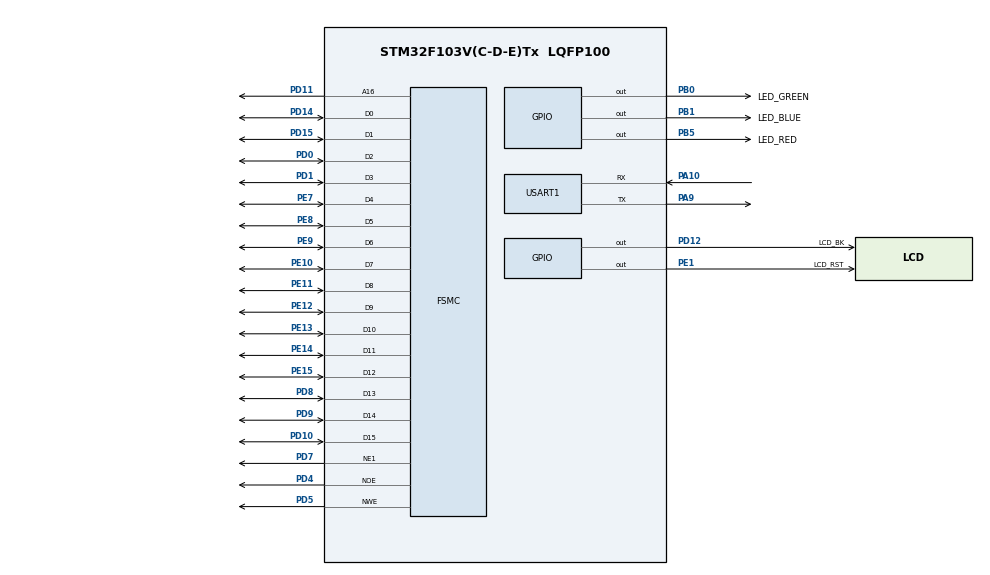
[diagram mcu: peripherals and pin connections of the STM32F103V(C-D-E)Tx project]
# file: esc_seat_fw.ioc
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Dma.Request0=USART1_RX
Dma.USART1_RX.0.Direction=DMA_PERIPH_TO_MEMORY
Dma.USART1_RX.0.Instance=DMA1_Channel5
Dma.USART1_RX.0.MemDataAlignment=DMA_MDATAALIGN_BYTE
Dma.USART1_RX.0.MemInc=DMA_MINC_ENABLE
Dma.USART1_RX.0.Mode=DMA_CIRCULAR
Dma.USART1_RX.0.PeriphDataAlignment=DMA_PDATAALIGN_BYTE
Dma.USART1_RX.0.PeriphInc=DMA_PINC_DISABLE
Dma.USART1_RX.0.Priority=DMA_PRIORITY_LOW
FSMC.AddressSetupTime1=1
FSMC.BusTurnAroundDuration1=0
FSMC.DataSetupTime1=1
Mcu.Family=STM32F1
Mcu.Name=STM32F103V(C-D-E)Tx
Mcu.Package=LQFP100
NVIC.DMA1_Channel5_IRQn=true\:0\:0\:false\:false\:true\:false\:true\:true
NVIC.PriorityGroup=NVIC_PRIORITYGROUP_4
NVIC.USART1_IRQn=true\:0\:0\:false\:false\:true\:true\:true\:true
OSC_IN.Mode=HSE-External-Oscillator
OSC_IN.Signal=RCC_OSC_IN
OSC_OUT.Mode=HSE-External-Oscillator
OSC_OUT.Signal=RCC_OSC_OUT
PA10.Mode=Asynchronous
PA10.Signal=USART1_RX
PA13.Mode=Serial_Wire
PA13.Signal=SYS_JTMS-SWDIO
PA14.Mode=Serial_Wire
PA14.Signal=SYS_JTCK-SWCLK
PA9.Mode=Asynchronous
PA9.Signal=USART1_TX
PB0.GPIO_Label=LED_GREEN
PB0.PinState=GPIO_PIN_SET
PB0.Signal=GPIO_Output
PB1.GPIO_Label=LED_BLUE
PB1.PinState=GPIO_PIN_SET
PB1.Signal=GPIO_Output
PB5.GPIO_Label=LED_RED
PB5.PinState=GPIO_PIN_SET
PB5.Signal=GPIO_Output
PD0.Mode=16b-d1
PD0.Signal=FSMC_D2
PD1.Mode=16b-d1
PD1.Signal=FSMC_D3
PD10.Mode=16b-d1
PD10.Signal=FSMC_D15
PD11.Mode=A16_1
PD11.Signal=FSMC_A16
PD12.GPIO_Label=LCD_BK
PD12.PinState=GPIO_PIN_SET
PD12.Signal=GPIO_Output
PD14.Mode=16b-d1
PD14.Signal=FSMC_D0
PD15.Mode=16b-d1
PD15.Signal=FSMC_D1
PD4.Mode=Lcd1
PD4.Signal=FSMC_NOE
PD5.Mode=Lcd1
PD5.Signal=FSMC_NWE
PD7.Mode=NorPsramChipSelect1_1
PD7.Signal=FSMC_NE1
PD8.Mode=16b-d1
PD8.Signal=FSMC_D13
PD9.Mode=16b-d1
PD9.Signal=FSMC_D14
PE1.GPIO_Label=LCD_RST
PE1.Signal=GPIO_Output
PE10.Mode=16b-d1
PE10.Signal=FSMC_D7
PE11.Mode=16b-d1
PE11.Signal=FSMC_D8
PE12.Mode=16b-d1
PE12.Signal=FSMC_D9
PE13.Mode=16b-d1
PE13.Signal=FSMC_D10
PE14.Mode=16b-d1
PE14.Signal=FSMC_D11
PE15.Mode=16b-d1
PE15.Signal=FSMC_D12
PE7.Mode=16b-d1
PE7.Signal=FSMC_D4
PE8.Mode=16b-d1
PE8.Signal=FSMC_D5
PE9.Mode=16b-d1
PE9.Signal=FSMC_D6
ProjectManager.HeapSize=0x200
ProjectManager.StackSize=0x400
ProjectManager.TargetToolchain=CMake
RCC.APB1Freq_Value=8000000
RCC.APB2Freq_Value=8000000
USART1.VirtualMode=VM_ASYNC
board=custom

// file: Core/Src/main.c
/* USER CODE BEGIN Header */
/**
  ******************************************************************************
  * @file           : main.c
  * @brief          : Main program body
  ******************************************************************************
  * @attention
  *
  * Copyright (c) 2026 STMicroelectronics.
  * All rights reserved.
  *
  * This software is licensed under terms that can be found in the LICENSE file
  * in the root directory of this software component.
  * If no LICENSE file comes with this software, it is provided AS-IS.
  *
  ******************************************************************************
  */
/* USER CODE END Header */
#include "main.h"

/* USER CODE BEGIN Includes */
#include "AppSystem.h"
#include "Scheduler.h"
/* USER CODE END Includes */

UART_HandleTypeDef huart1;
DMA_HandleTypeDef hdma_usart1_rx;

SRAM_HandleTypeDef hsram1;

void SystemClock_Config(void);
static void MX_GPIO_Init(void);
static void MX_DMA_Init(void);
static void MX_USART1_UART_Init(void);
static void MX_FSMC_Init(void);

int main(void)
{

  /* MCU Configuration--------------------------------------------------------*/

  /* Reset of all peripherals, Initializes the Flash interface and the Systick. */
  HAL_Init();

  /* Configure the system clock */
  SystemClock_Config();

  /* Initialize all configured peripherals */
  MX_GPIO_Init();
  MX_DMA_Init();
  MX_USART1_UART_Init();
  MX_FSMC_Init();
  /* USER CODE BEGIN 2 */
  AppSystem_Init();
  /* USER CODE END 2 */

  /* Infinite loop */
  while (1)
  {

    /* USER CODE BEGIN 3 */
    Scheduler_MainFunction();

  }
  /* USER CODE END 3 */
}

void SystemClock_Config(void)
{
  RCC_OscInitTypeDef RCC_OscInitStruct = {0};
  RCC_ClkInitTypeDef RCC_ClkInitStruct = {0};

  /** Initializes the RCC Oscillators according to the specified parameters
  * in the RCC_OscInitTypeDef structure.
  */
  RCC_OscInitStruct.OscillatorType = RCC_OSCILLATORTYPE_HSI;
  RCC_OscInitStruct.HSIState = RCC_HSI_ON;
  RCC_OscInitStruct.HSICalibrationValue = RCC_HSICALIBRATION_DEFAULT;
  RCC_OscInitStruct.PLL.PLLState = RCC_PLL_NONE;
  if (HAL_RCC_OscConfig(&RCC_OscInitStruct) != HAL_OK)
  {
    Error_Handler();
  }

  /** Initializes the CPU, AHB and APB buses clocks
  */
  RCC_ClkInitStruct.ClockType = RCC_CLOCKTYPE_HCLK|RCC_CLOCKTYPE_SYSCLK
                              |RCC_CLOCKTYPE_PCLK1|RCC_CLOCKTYPE_PCLK2;
  RCC_ClkInitStruct.SYSCLKSource = RCC_SYSCLKSOURCE_HSI;
  RCC_ClkInitStruct.AHBCLKDivider = RCC_SYSCLK_DIV1;
  RCC_ClkInitStruct.APB1CLKDivider = RCC_HCLK_DIV1;
  RCC_ClkInitStruct.APB2CLKDivider = RCC_HCLK_DIV1;

  if (HAL_RCC_ClockConfig(&RCC_ClkInitStruct, FLASH_LATENCY_0) != HAL_OK)
  {
    Error_Handler();
  }
}

static void MX_USART1_UART_Init(void)
{

  huart1.Instance = USART1;
  huart1.Init.BaudRate = 115200;
  huart1.Init.WordLength = UART_WORDLENGTH_8B;
  huart1.Init.StopBits = UART_STOPBITS_1;
  huart1.Init.Parity = UART_PARITY_NONE;
  huart1.Init.Mode = UART_MODE_TX_RX;
  huart1.Init.HwFlowCtl = UART_HWCONTROL_NONE;
  huart1.Init.OverSampling = UART_OVERSAMPLING_16;
  if (HAL_UART_Init(&huart1) != HAL_OK)
  {
    Error_Handler();
  }

}

static void MX_DMA_Init(void)
{

  /* DMA controller clock enable */
  __HAL_RCC_DMA1_CLK_ENABLE();

  /* DMA interrupt init */
  /* DMA1_Channel5_IRQn interrupt configuration */
  HAL_NVIC_SetPriority(DMA1_Channel5_IRQn, 0, 0);
  HAL_NVIC_EnableIRQ(DMA1_Channel5_IRQn);

}

static void MX_GPIO_Init(void)
{
  GPIO_InitTypeDef GPIO_InitStruct = {0};

  /* GPIO Ports Clock Enable */
  __HAL_RCC_GPIOB_CLK_ENABLE();
  __HAL_RCC_GPIOE_CLK_ENABLE();
  __HAL_RCC_GPIOD_CLK_ENABLE();
  __HAL_RCC_GPIOA_CLK_ENABLE();

  /*Configure GPIO pin Output Level */
  HAL_GPIO_WritePin(GPIOB, LED_GREEN_Pin|LED_BLUE_Pin|LED_RED_Pin, GPIO_PIN_SET);

  /*Configure GPIO pin Output Level */
  HAL_GPIO_WritePin(LCD_BK_GPIO_Port, LCD_BK_Pin, GPIO_PIN_SET);

  /*Configure GPIO pin Output Level */
  HAL_GPIO_WritePin(LCD_RST_GPIO_Port, LCD_RST_Pin, GPIO_PIN_RESET);

  /*Configure GPIO pins : LED_GREEN_Pin LED_BLUE_Pin LED_RED_Pin */
  GPIO_InitStruct.Pin = LED_GREEN_Pin|LED_BLUE_Pin|LED_RED_Pin;
  GPIO_InitStruct.Mode = GPIO_MODE_OUTPUT_PP;
  GPIO_InitStruct.Pull = GPIO_NOPULL;
  GPIO_InitStruct.Speed = GPIO_SPEED_FREQ_LOW;
  HAL_GPIO_Init(GPIOB, &GPIO_InitStruct);

  /*Configure GPIO pin : LCD_BK_Pin */
  GPIO_InitStruct.Pin = LCD_BK_Pin;
  GPIO_InitStruct.Mode = GPIO_MODE_OUTPUT_PP;
  GPIO_InitStruct.Pull = GPIO_NOPULL;
  GPIO_InitStruct.Speed = GPIO_SPEED_FREQ_LOW;
  HAL_GPIO_Init(LCD_BK_GPIO_Port, &GPIO_InitStruct);

  /*Configure GPIO pin : LCD_RST_Pin */
  GPIO_InitStruct.Pin = LCD_RST_Pin;
  GPIO_InitStruct.Mode = GPIO_MODE_OUTPUT_PP;
  GPIO_InitStruct.Pull = GPIO_NOPULL;
  GPIO_InitStruct.Speed = GPIO_SPEED_FREQ_LOW;
  HAL_GPIO_Init(LCD_RST_GPIO_Port, &GPIO_InitStruct);

}

/* FSMC initialization function */
static void MX_FSMC_Init(void)
{

  FSMC_NORSRAM_TimingTypeDef Timing = {0};

  /** Perform the SRAM1 memory initialization sequence
  */
  hsram1.Instance = FSMC_NORSRAM_DEVICE;
  hsram1.Extended = FSMC_NORSRAM_EXTENDED_DEVICE;
  /* hsram1.Init */
  hsram1.Init.NSBank = FSMC_NORSRAM_BANK1;
  hsram1.Init.DataAddressMux = FSMC_DATA_ADDRESS_MUX_DISABLE;
  hsram1.Init.MemoryType = FSMC_MEMORY_TYPE_SRAM;
  hsram1.Init.MemoryDataWidth = FSMC_NORSRAM_MEM_BUS_WIDTH_16;
  hsram1.Init.BurstAccessMode = FSMC_BURST_ACCESS_MODE_DISABLE;
  hsram1.Init.WaitSignalPolarity = FSMC_WAIT_SIGNAL_POLARITY_LOW;
  hsram1.Init.WrapMode = FSMC_WRAP_MODE_DISABLE;
  hsram1.Init.WaitSignalActive = FSMC_WAIT_TIMING_BEFORE_WS;
  hsram1.Init.WriteOperation = FSMC_WRITE_OPERATION_ENABLE;
  hsram1.Init.WaitSignal = FSMC_WAIT_SIGNAL_DISABLE;
  hsram1.Init.ExtendedMode = FSMC_EXTENDED_MODE_DISABLE;
  hsram1.Init.AsynchronousWait = FSMC_ASYNCHRONOUS_WAIT_DISABLE;
  hsram1.Init.WriteBurst = FSMC_WRITE_BURST_DISABLE;
  /* Timing */
  Timing.AddressSetupTime = 1;
  Timing.AddressHoldTime = 15;
  Timing.DataSetupTime = 1;
  Timing.BusTurnAroundDuration = 0;
  Timing.CLKDivision = 16;
  Timing.DataLatency = 17;
  Timing.AccessMode = FSMC_ACCESS_MODE_A;
  /* ExtTiming */

  if (HAL_SRAM_Init(&hsram1, &Timing, NULL) != HAL_OK)
  {
    Error_Handler( );
  }

  /** Disconnect NADV
  */

  __HAL_AFIO_FSMCNADV_DISCONNECTED();

}

void Error_Handler(void)
{
  __disable_irq();
  while (1)
  {
  }
}
